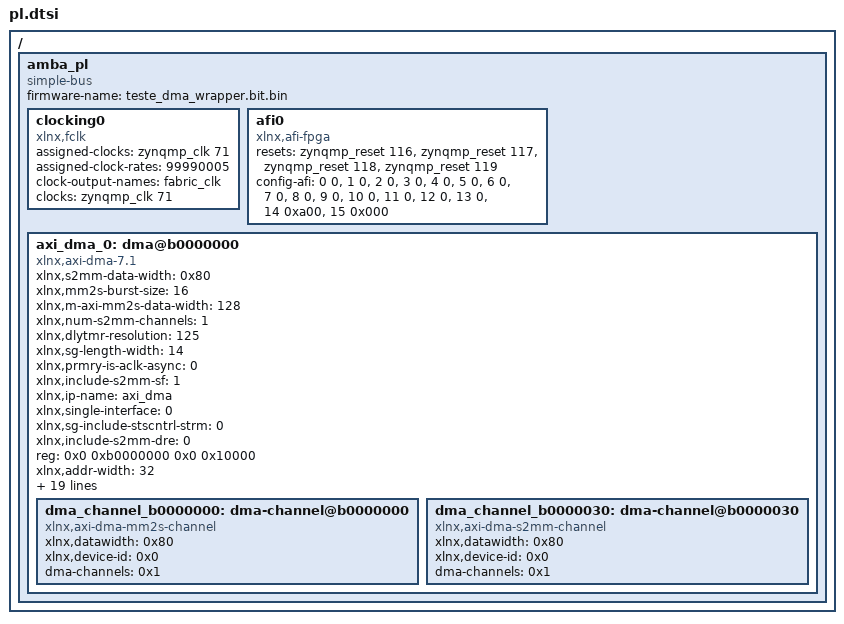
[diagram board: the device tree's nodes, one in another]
/ {
	amba_pl: amba_pl {
		ranges;
		compatible = "simple-bus";
		#address-cells = <2>;
		#size-cells = <2>;
		firmware-name = "teste_dma_wrapper.bit.bin";
		clocking0: clocking0 {
			compatible = "xlnx,fclk";
			status = "okay";
			assigned-clocks = <&zynqmp_clk 71>;
			assigned-clock-rates = <99990005>;
			#clock-cells = <0>;
			clock-output-names = "fabric_clk";
			clocks = <&zynqmp_clk 71>;
		};
		afi0: afi0 {
			status = "okay";
			compatible = "xlnx,afi-fpga";
			resets = <&zynqmp_reset 116>, <&zynqmp_reset 117>, <&zynqmp_reset 118>, <&zynqmp_reset 119>;
			config-afi = < 0 0>, <1 0>, <2 0>, <3 0>, <4 0>, <5 0>, <6 0>, <7 0>, <8 0>, <9 0>, <10 0>, <11 0>, <12 0>, <13 0>, <14 0xa00>, <15 0x000>;
		};
		axi_dma_0: dma@b0000000 {
			compatible = "xlnx,axi-dma-7.1" , "xlnx,axi-dma-1.00.a";
			xlnx,s2mm-data-width = <0x80>;
			xlnx,mm2s-burst-size = <16>;
			xlnx,m-axi-mm2s-data-width = <128>;
			xlnx,num-s2mm-channels = <1>;
			xlnx,dlytmr-resolution = <125>;
			xlnx,sg-length-width = <14>;
			xlnx,prmry-is-aclk-async = <0>;
			xlnx,include-s2mm-sf = <1>;
			#dma-cells = <1>;
			xlnx,ip-name = "axi_dma";
			xlnx,single-interface = <0>;
			xlnx,sg-include-stscntrl-strm = <0>;
			xlnx,include-s2mm-dre = <0>;
			reg = <0x0 0xb0000000 0x0 0x10000>;
			xlnx,addr-width = <32>;
			xlnx,include-s2mm = <1>;
			clocks = <&zynqmp_clk 71>, <&zynqmp_clk 71>, <&zynqmp_clk 71>;
			xlnx,s-axis-s2mm-tdata-width = <128>;
			xlnx,micro-dma = <0>;
			xlnx,increase-throughput = <0>;
			xlnx,mm2s-data-width = <0x80>;
			xlnx,addrwidth = <0x20>;
			xlnx,sg-use-stsapp-length = <0>;
			xlnx,m-axis-mm2s-tdata-width = <128>;
			xlnx,edk-iptype = "PERIPHERAL";
			xlnx,s2mm-burst-size = <16>;
			xlnx,m-axi-s2mm-data-width = <128>;
			xlnx,num-mm2s-channels = <1>;
			xlnx,enable-multi-channel = <0>;
			status = "okay";
			xlnx,include-mm2s-sf = <1>;
			clock-names = "m_axi_mm2s_aclk" , "m_axi_s2mm_aclk" , "s_axi_lite_aclk";
			xlnx,include-mm2s = <1>;
			xlnx,include-mm2s-dre = <0>;
			xlnx,name = "axi_dma_0";
			dma_channel_b0000000: dma-channel@b0000000 {
				xlnx,datawidth = <0x80>;
				xlnx,device-id = <0x0>;
				compatible = "xlnx,axi-dma-mm2s-channel";
				dma-channels = <0x1>;
			};
			dma_channel_b0000030: dma-channel@b0000030 {
				xlnx,datawidth = <0x80>;
				xlnx,device-id = <0x0>;
				compatible = "xlnx,axi-dma-s2mm-channel";
				dma-channels = <0x1>;
			};
		};
	};
};
